# STM32H753V register map
File version: 2.5
CPU: CM7 r0p1, little endian, MPU, FPU, 4 interrupt priority bits
Registers are 32-bit, read-write, reset 0x0 unless marked. A register's access mark holds for its fields unless they carry their own. Offsets are from the block's base; [hi:lo] are bit positions; lines under a group give offsets from that group; {n}, {i} and the like mark numbered series; 'fields as' and 'values as' point back to an identical list.

## BDMA
Base 0x58025400
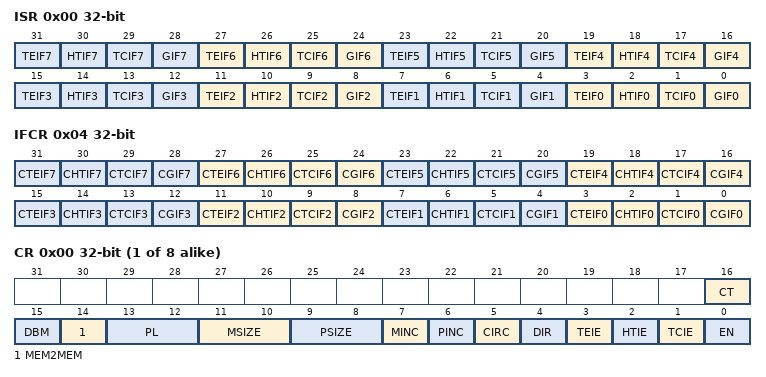
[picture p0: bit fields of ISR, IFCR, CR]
0x00 ISR ro — BDMA interrupt status register
  [4n+3] TEIF{n} (n=0..7) — Channel {n} Transfer Error flag
    0=NoError (No transfer error on channel x); 1=Error (A transfer error occurred on channel x)
  [4n+2] HTIF{n} (n=0..7) — Channel {n} Half Transfer Complete flag
    0=NotHalf (No half transfer event on channel x); 1=Half (A half transfer event occurred on channel x)
  [4n+1] TCIF{n} (n=0..7) — Channel {n} Transfer Complete flag
    0=NotComplete (No transfer complete event on channel x); 1=Complete (A transfer complete event occurred on channel x)
  [4n] GIF{n} (n=0..7) — Channel {n} Global interrupt flag
    0=NoEvent (No TE, HT or TC event on channel x); 1=Event (A TE, HT or TC event occurred on channel x)
0x04 IFCR wo — BDMA interrupt flag clear register
  [4n+3] CTEIF{n} (n=0..7) — Channel {n} Transfer Error clear
    1=Clear the corresponding TEIFx flag
  [4n+2] CHTIF{n} (n=0..7) — Channel {n} Half Transfer clear
    1=Clear the corresponding HTIFx flag
  [4n+1] CTCIF{n} (n=0..7) — Channel {n} Transfer Complete clear
    1=Clear the corresponding TCIFx flag
  [4n] CGIF{n} (n=0..7) — Channel {n} Global interrupt clear
    1=Clear the corresponding CGIFx flag
{0x8+0x14*i} CH{i} (i=0..7) group — Channel cluster: CCR?, CNDTR?, CPAR?, CM0AR? and CM1AR? registers
  0x00 CR — BDMA channel 0 configuration register
    [16] CT — current target memory of DMA transfer in double-buffer mode This bit is toggled by hardware at the end of each channel transfer in double-buffer mode. Note: this bit is set and cleared by software. It must not be written when the channel is enabled (EN = 1). It is read-only when the channel is enabled (EN = 1).
      0=Memory0 (The current target memory is Memory 0); 1=Memory1 (The current target memory is Memory 1)
    [15] DBM — double-buffer mode This bit must be set only in memory-to-peripheral and peripheral-to-memory transfers (MEM2MEM=0). The CIRC bit must also be set in double buffer mode. Note: this bit is set and cleared by software. It must not be written when the channel is enabled (EN = 1). It is not read-only when the channel is enabled (EN = 1).
      0=Disabled (No buffer switching at the end of transfer); 1=Enabled (Memory target switched at the end of the DMA transfer)
    [14] MEM2MEM — memory-to-memory mode Note: this bit is set and cleared by software. It must not be written when the channel is enabled (EN = 1). It is read-only when the channel is enabled (EN = 1).
      0=Disabled (Memory-to-memory mode disabled); 1=Enabled (Memory-to-memory mode enabled)
    [13:12] PL — priority level Note: this field is set and cleared by software. It must not be written when the channel is enabled (EN = 1). It is read-only when the channel is enabled (EN = 1).
      0=Low; 1=Medium; 2=High; 3=VeryHigh
    [11:10] MSIZE — memory size Defines the data size of each DMA transfer to the identified memory. In memory-to-memory mode, this field identifies the memory source if DIR = 1 and the memory destination if DIR = 0. In peripheral-to-peripheral mode, this field identifies the peripheral source if DIR = 1 and the peripheral destination if DIR = 0. Note: this field is set and cleared by software. It must not be written when the channel is enabled (EN = 1). It is read-only when the channel is enabled (EN = 1).
      0=Bits8 (Byte (8-bit)); 1=Bits16 (Half-word (16-bit)); 2=Bits32 (Word (32-bit))
    [9:8] PSIZE — peripheral size Defines the data size of each DMA transfer to the identified peripheral. In memory-to-memory mode, this field identifies the memory destination if DIR = 1 and the memory source if DIR = 0. In peripheral-to-peripheral mode, this field identifies the peripheral destination if DIR = 1 and the peripheral source if DIR = 0. Note: this field is set and cleared by software. It must not be written when the channel is enabled (EN = 1). It is read-only when the channel is enabled (EN = 1).
      values as MSIZE
    [7] MINC — memory increment mode Defines the increment mode for each DMA transfer to the identified memory. In memory-to-memory mode, this field identifies the memory source if DIR = 1 and the memory destination if DIR = 0. In peripheral-to-peripheral mode, this field identifies the peripheral source if DIR = 1 and the peripheral destination if DIR = 0. Note: this bit is set and cleared by software. It must not be written when the channel is enabled (EN = 1). It is read-only when the channel is enabled (EN = 1).
      0=Fixed (Address pointer is fixed); 1=Incremented (Address pointer is incremented after each data transfer)
    [6] PINC — peripheral increment mode Defines the increment mode for each DMA transfer to the identified peripheral. n memory-to-memory mode, this field identifies the memory destination if DIR = 1 and the memory source if DIR = 0. In peripheral-to-peripheral mode, this field identifies the peripheral destination if DIR = 1 and the peripheral source if DIR = 0. Note: this bit is set and cleared by software. It must not be written when the channel is enabled (EN = 1). It is read-only when the channel is enabled (EN = 1).
      values as MINC
    [5] CIRC — circular mode Note: this bit is set and cleared by software. It must not be written when the channel is enabled (EN = 1). It is not read-only when the channel is enabled (EN = 1).
      0=Disabled (Circular mode disabled); 1=Enabled (Circular mode enabled)
    [4] DIR — data transfer direction This bit must be set only in memory-to-peripheral and peripheral-to-memory modes. Source attributes are defined by PSIZE and PINC, plus the BDMA_CPARx register. This is still valid in a memory-to-memory mode. Destination attributes are defined by MSIZE and MINC, plus the BDMA_CM0/1ARx register. This is still valid in a peripheral-to-peripheral mode. Destination attributes are defined by PSIZE and PINC, plus the BDMA_CPARx register. This is still valid in a memory-to-memory mode. Source attributes are defined by MSIZE and MINC, plus the BDMA_CM0/1ARx register. This is still valid in a peripheral-to-peripheral mode. Note: this bit is set and cleared by software. It must not be written when the channel is enabled (EN = 1). It is read-only when the channel is enabled (EN = 1).
      0=PeripheralToMemory; 1=MemoryToPeripheral
    [3] TEIE — transfer error interrupt enable Note: this bit is set and cleared by software. It must not be written when the channel is enabled (EN = 1). It is not read-only when the channel is enabled (EN = 1).
      0=Disabled (TE interrupt disabled); 1=Enabled (TE interrupt enabled)
    [2] HTIE — half transfer interrupt enable Note: this bit is set and cleared by software. It must not be written when the channel is enabled (EN = 1). It is not read-only when the channel is enabled (EN = 1).
      0=Disabled (HT interrupt disabled); 1=Enabled (HT interrupt enabled)
    [1] TCIE — transfer complete interrupt enable Note: this bit is set and cleared by software. It must not be written when the channel is enabled (EN = 1). It is not read-only when the channel is enabled (EN = 1).
      0=Disabled (TC interrupt disabled); 1=Enabled (TC interrupt enabled)
    [0] EN — channel enable When a channel transfer error occurs, this bit is cleared by hardware. It can not be set again by software (channel x re-activated) until the TEIFx bit of the BDMA_ISR register is cleared (by setting the CTEIFx bit of the BDMA_IFCR register). Note: this bit is set and cleared by software.
      0=Disabled (Channel disabled); 1=Enabled (Channel enabled)
  0x04 NDTR
    [15:0] NDT — number of data to transfer (0 to 216 - 1) This field is updated by hardware when the channel is enabled: It is decremented after each single BDMA 'read followed by write' transfer, indicating the remaining amount of data items to transfer. It is kept at zero when the programmed amount of data to transfer is reached, if the channel is not in circular mode (CIRC = 0 in the BDMA_CCRx register). It is reloaded automatically by the previously programmed value, when the transfer is complete, if the channel is in circular mode (CIRC = 1). If this field is zero, no transfer can be served whatever the channel status (enabled or not). Note: this field is set and cleared by software. It must not be written when the channel is enabled (EN = 1). It is read-only when the channel is enabled (EN = 1).
  0x08 PAR
    [31:0] PA — peripheral address It contains the base address of the peripheral data register from/to which the data is read/written. When PSIZE[1:0] = 01 (16 bits), bit 0 of PA[31:0] is ignored. Access is automatically aligned to a half-word address. When PSIZE = 10 (32 bits), bits 1 and 0 of PA[31:0] are ignored. Access is automatically aligned to a word address. In memory-to-memory mode, this register identifies the memory destination address if DIR = 1 and the memory source address if DIR = 0. In peripheral-to-peripheral mode, this register identifies the peripheral destination address DIR = 1 and the peripheral source address if DIR = 0. Note: this register is set and cleared by software. It must not be written when the channel is enabled (EN = 1). It is not read-only when the channel is enabled (EN = 1).
  0x0C M0AR
    [31:0] MA — peripheral address It contains the base address of the memory from/to which the data is read/written. When MSIZE[1:0] = 01 (16 bits), bit 0 of MA[31:0] is ignored. Access is automatically aligned to a half-word address. When MSIZE = 10 (32 bits), bits 1 and 0 of MA[31:0] are ignored. Access is automatically aligned to a word address. In memory-to-memory mode, this register identifies the memory source address if DIR = 1 and the memory destination address if DIR = 0. In peripheral-to-peripheral mode, this register identifies the peripheral source address DIR = 1 and the peripheral destination address if DIR = 0. Note: this register is set and cleared by software. It must not be written when the channel is enabled (EN = 1). It is not read-only when the channel is enabled (EN = 1).
  0x10 M1AR
    fields as CH0.M0AR
